# PIC32MK1024MCF064 device description
Architecture: MIPS; Family: PIC32MK; Series: PIC32MK
Registers are 32-bit, read-write, no defined reset value unless marked. A register's access mark holds for its fields unless they carry their own. Offsets are from the block's base; [hi:lo] are bit positions; {n}, {i} and the like mark numbered series; 'fields as' and 'values as' point back to an identical list.

## CDAC
Instances: CDAC 0x1f82c200 in periph_pb2_std
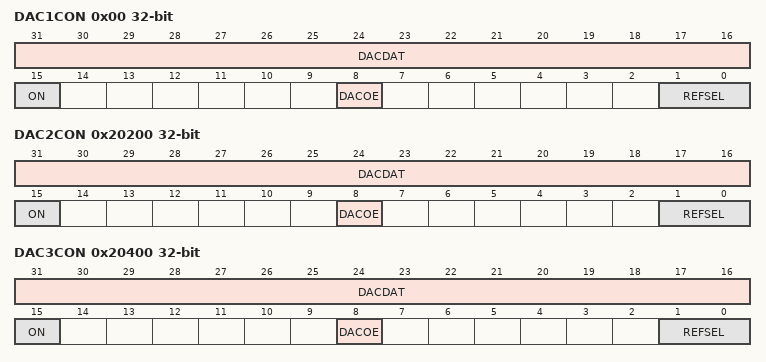
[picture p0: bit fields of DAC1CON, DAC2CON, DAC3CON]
0x00 DAC1CON — CDAC Control Register
  [31:16] DACDAT
  [15] ON — CDAC Enable bit
    1=The CDAC is enabled; 0=The CDAC is disabled
  [8] DACOE — CDAC Output Buffer Enable bit
    1=Output is enabled; CDAC voltage is connected to the pin; 0=Output is disabled; drive to pin is floating
  [1:0] REFSEL — Reference Source Select bits
    3=Positive reference voltage = AVDD; 2=No reference selected (no reference current consumption); 1=No reference selected (no reference current consumption); 0=No reference selected (no reference current consumption)
0x20200 DAC2CON — CDAC Control Register
  fields as DAC1CON
0x20400 DAC3CON — CDAC Control Register
  fields as DAC1CON

## CFG
Instances: CFG 0x1f800000 in periph_pb1_std
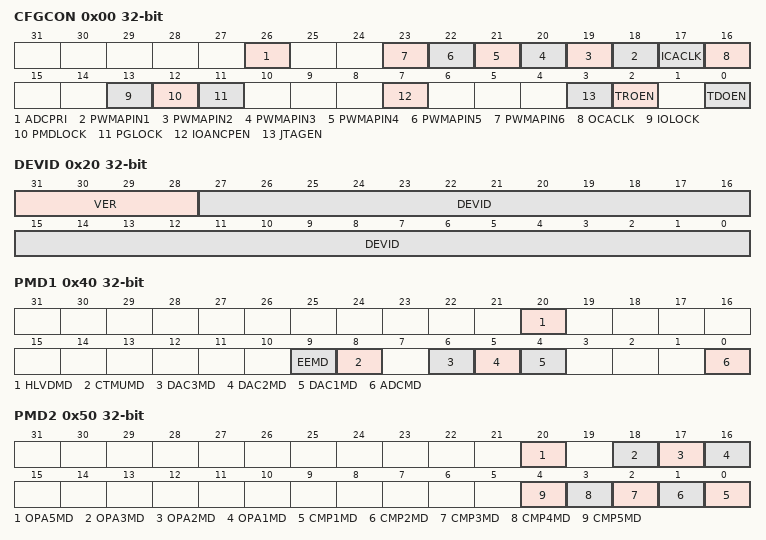
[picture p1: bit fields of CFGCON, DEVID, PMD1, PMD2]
0x00 CFGCON
  [26] ADCPRI, [n+17] PWMAPIN{n} (n=1..6), [17] ICACLK, [16] OCACLK, [13] IOLOCK, [12] PMDLOCK, [11] PGLOCK, [7] IOANCPEN, [3] JTAGEN, [2] TROEN, [0] TDOEN
0x20 DEVID
  [31:28] VER, [27:0] DEVID
0x30 SYSKEY
0x40 PMD1
  [20] HLVDMD, [9] EEMD, [8] CTMUMD, [6] DAC3MD, [5] DAC2MD, [4] DAC1MD, [0] ADCMD
0x50 PMD2
  [20] OPA5MD, [18] OPA3MD, [17] OPA2MD, [16] OPA1MD, [n-1] CMP{n}MD (n=1..5)
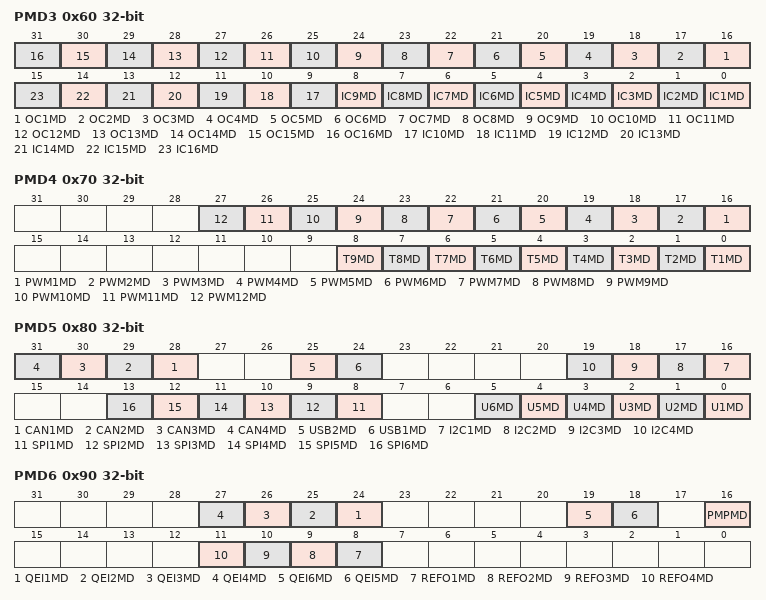
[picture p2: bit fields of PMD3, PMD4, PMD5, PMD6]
0x60 PMD3
  [n+15] OC{n}MD (n=1..16), [n-1] IC{n}MD (n=1..16)
0x70 PMD4
  [n+15] PWM{n}MD (n=1..12), [n-1] T{n}MD (n=1..9)
0x80 PMD5
  [n+27] CAN{n}MD (n=1..4), [25] USB2MD, [24] USB1MD, [n+15] I2C{n}MD (n=1..4), [n+7] SPI{n}MD (n=1..6), [n-1] U{n}MD (n=1..6)
0x90 PMD6
  [n+23] QEI{n}MD (n=1..4), [19] QEI6MD, [18] QEI5MD, [16] PMPMD, [n+7] REFO{n}MD (n=1..4)
0xA0 PMD7
  [4] DMAMD
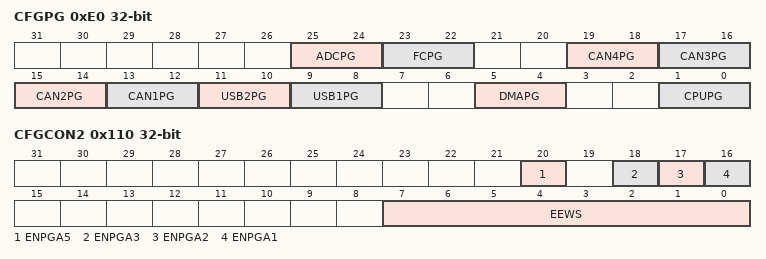
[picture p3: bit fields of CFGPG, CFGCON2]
0xE0 CFGPG — PERMISSION GROUP CONFIGURATION REGISTER
  [25:24] ADCPG — ADC Permission bits
    {v}=Read access if RDPER = 1; write access if WRPER<{v}> = 1 (v=0..3)
  [23:22] FCPG — Flash Control Permission Group bits
    values as ADCPG
  [19:18] CAN4PG
  [17:16] CAN3PG — CAN3 Module Permission Group bits
    values as ADCPG
  [15:14] CAN2PG — CAN2 Module Permission Group bits
    values as ADCPG
  [13:12] CAN1PG — CAN1 Module Permission Group bits
    values as ADCPG
  [11:10] USB2PG — USB2 Module Permission Group bits
    values as ADCPG
  [9:8] USB1PG — USB1 Module Permission Group bits
    values as ADCPG
  [5:4] DMAPG — DMA Module Permission Group bits
    values as ADCPG
  [1:0] CPUPG — CPU Permission Group bits
    values as ADCPG
0x110 CFGCON2 — EE DATA AND OP AMP CONFIGURATION REGISTER
  [20] ENPGA5 — Enable Op amp 5 to PGA Mode bit
    1=Op amp enable 1x gain mode; 0=Op amp 3-terminal standard operation (default)
  [18] ENPGA3 — Enable Op amp 3 to PGA Mode bit
    values as ENPGA5
  [17] ENPGA2 — Enable Op amp 2 to PGA Mode bit
    values as ENPGA5
  [16] ENPGA1 — Enable Op amp 1 to PGA Mode bit
    values as ENPGA5
  [7:0] EEWS
Value list DEVID__VER: 0x10000000=Revision A1; 0x20000000=Revision A2

## CTMU
Instances: CTMU 0x1f82d000 in periph_pb2_std
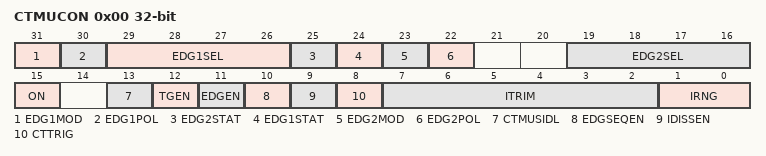
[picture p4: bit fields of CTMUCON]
0x00 CTMUCON — CTMU Control Register
  [31] EDG1MOD — Edge1 Edge Sampling Select bit
    1=Input is edge-sensitive; 0=Input is level-sensitive
  [30] EDG1POL — Edge 1 Polarity Select bit
    1=Edge1 programmed for a positive edge response; 0=Edge1 programmed for a negative edge response
  [29:26] EDG1SEL — Edge 1 Source Select bits
    14=C2OUT pin is selected; 13=C1OUT pin is selected; {v}=IC{v-6} Capture Event is selected (v=7..12); 6=OC4 Capture Event is selected; 5=OC3 Capture Event is selected; 4=OC2 Capture Event is selected; 3=CTED1 pin is selected; 2=CTED2 pin is selected; 1=OC1 Compare Event is selected; 0=Timer1 Event is selected
  [25] EDG2STAT — Edge2 Status bit
    1=Edge2 has occurred; 0=Edge2 has not occurred
  [24] EDG1STAT — Edge1 Status bit
    1=Edge1 has occurred; 0=Edge1 has not occurred
  [23] EDG2MOD — Edge2 Edge Sampling Select bit
    1=Input is edge-sensitive; 0=Input is level-sensitive
  [22] EDG2POL — Edge 2 Polarity Select bit
    1=Edge2 programmed for a positive edge response; 0=Edge2 programmed for a negative edge response
  [19:16] EDG2SEL — Edge 2 Source Select bits
    56=C2OUT pin is selected; 52=C1OUT pin is selected; 48=PBCLK3; 44=IC5 Capture Event is selected; 40=IC4 Capture Event is selected; 36=IC3 Capture Event is selected; 32=IC2 Capture Event is selected; 28=IC1 Capture Event is selected; 24=OC4 Capture Event is selected; 20=OC3 Capture Event is selected; 16=OC2 Capture Event is selected; 12=CTED1 pin is selected; 8=CTED2 pin is selected; 4=OC1 Compare Event is selected; 0=Timer1 Event is selected
  [15] ON — ON Enable bit
    1=Module is enabled; 0=OFF (Module is disabled)
  [13] CTMUSIDL — Stop-in-Idle Mode bit
    1=Discontinue module operation when device enters Idle mode; 0=Continue module operation in Idle mode
  [12] TGEN — Time Generation Enable bit
    1=Enables edge delay generation; 0=Disables edge delay generation
  [11] EDGEN — Edge Enable bit
    1=Edges are not blocked; 0=Edges are blocked
  [10] EDGSEQEN — Edge Sequence Enable bit
    1=Edge1 must occur before Edge2 can occur; 0=No edge sequence is needed
  [9] IDISSEN — Analog Current Source Control bit
    1=Analog current source output is grounded; 0=Analog current source output is not grounded
  [8] CTTRIG — Trigger Control bit
    1=Trigger output is enabled; 0=Trigger output is disabled
  [7:2] ITRIM — Current Source Trim bits
    31=Maximum positive change from nominal current; 1=Minimum positive change from nominal current; 0=Nominal current output specified by IRNG; 63=Minimum negative change from nominal current; 33=Maximum negative change from nominal current
  [1:0] IRNG — Current Range Select bits
    3=100 times base current; 2=10 times base current; 1=Base current level; 0=1000 times base current
